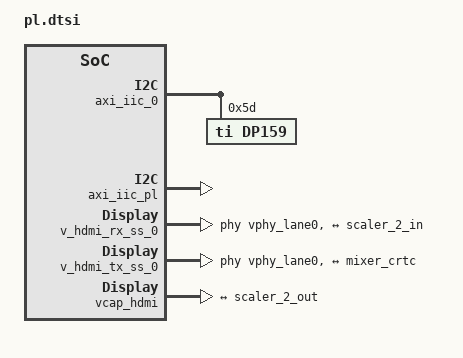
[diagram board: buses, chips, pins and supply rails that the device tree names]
/*
 * CAUTION: This file is automatically generated by Xilinx.
 * Version: XSCT 2018.3
 * Today is: Fri Feb  1 12:27:28 2019
 */


/ {
	amba_pl: amba_pl@0 {
		#address-cells = <2>;
		#size-cells = <2>;
		compatible = "simple-bus";
		ranges ;
		axi_iic_0: i2c@a000b000 {
			#address-cells = <1>;
			#size-cells = <0>;
			clock-names = "s_axi_aclk";
			clocks = <&misc_clk_0>;
			compatible = "xlnx,xps-iic-2.00.a";
			interrupt-names = "iic2intc_irpt";
			interrupt-parent = <&axi_intc_0>;
			interrupts = <4 2>;
			reg = <0x0 0xa000b000 0x0 0x1000>;
			
			dp159: hdmi-retimer@5d {
				status = "okay";
				compatible = "ti,dp159";
				reg = <0x5d>;
				#address-cells = <1>;
				#size-cells = <0>;
				#clock-cells = <0>;
			};
		};
		axi_iic_pl: i2c@a0003000 {
			#address-cells = <1>;
			#size-cells = <0>;
			clock-names = "s_axi_aclk";
			clocks = <&misc_clk_0>;
			compatible = "xlnx,xps-iic-2.00.a";
			interrupt-names = "iic2intc_irpt";
			interrupt-parent = <&axi_intc_0>;
			interrupts = <0 2>;
			reg = <0x0 0xa0003000 0x0 0x1000>;
		};
		axi_intc_0: interrupt-controller@a000a000 {
			#interrupt-cells = <2>;
			compatible = "xlnx,xps-intc-1.00.a";
			interrupt-controller ;
			interrupt-names = "irq";
			interrupt-parent = <&gic>;
			interrupts = <0 89 4>;
			reg = <0x0 0xa000a000 0x0 0x1000>;
			xlnx,kind-of-intr = <0x0>;
			xlnx,num-intr-inputs = <0x7>;
		};
		psu_ctrl_ipi: PERIPHERAL@ff380000 {
			/* This is a place holder node for a custom IP, user may need to update the entries */
			compatible = "xlnx,PERIPHERAL-1.0";
			reg = <0x0 0xff380000 0x0 0x80000>;
		};
		psu_message_buffers: PERIPHERAL@ff990000 {
			/* This is a place holder node for a custom IP, user may need to update the entries */
			compatible = "xlnx,PERIPHERAL-1.0";
			reg = <0x0 0xff990000 0x0 0x10000>;
		};
		v_frmbuf_wr_0: v_frmbuf_wr@b0000000 {
			/* This is a place holder node for a custom IP, user may need to update the entries */
			#dma-cells = <1>;
			compatible = "xlnx,axi-frmbuf-wr-v2";
			interrupt-names = "interrupt";
			interrupt-parent = <&axi_intc_0>;
			interrupts = <6 2>;
			reg = <0x0 0xb0000000 0x0 0x10000>;
			reset-gpios = <&gpio 80 1>;
			xlnx,dma-addr-width = <32>;
			xlnx,s-axi-ctrl-addr-width = <0x7>;
			xlnx,s-axi-ctrl-data-width = <0x20>;
			xlnx,vid-formats = "yuyv","uyvy","y8";
		};
		v_hdmi_rx_ss_0: v_hdmi_rx_ss@a0010000 {
			/* This is a place holder node for a custom IP, user may need to update the entries */
			compatible = "xlnx,v-hdmi-rx-ss-3.1";
			interrupt-names = "irq";
			interrupt-parent = <&axi_intc_0>;
			interrupts = <5 2>;
			reg = <0x0 0xa0010000 0x0 0x10000>;
			
			clocks = <&misc_clk_0>, <&misc_clk_1>;
			clock-names = "axi-lite", "video";
			
			phy-names = "hdmi-phy0", "hdmi-phy1", "hdmi-phy2";
			phys = <&vphy_lane0 0 1 1 0>, <&vphy_lane1 0 1 1 0>, <&vphy_lane2 0 1 1 0>;
			
			xlnx,input-pixels-per-clock = <0x2>;

			/*xlnx,add-mark-dbg = "false";
			xlnx,addr-width = <0xa>;
			xlnx,cd-invert = "false";

			xlnx,exdes-axilite-freq = <0x64>;
			xlnx,exdes-nidru = "true";
			xlnx,exdes-rx-pll-selection = <0x0>;
			xlnx,exdes-topology = <0x0>;
			xlnx,exdes-tx-pll-selection = <0x1>;
			xlnx,hdmi-fast-switch = "false";
			xlnx,hdmi-version = <0x3>;
			xlnx,hpd-invert = "false";
			xlnx,include-hdcp-1-4 = "false";
			xlnx,include-hdcp-2-2 = "false";
			xlnx,include-low-reso-vid = "false";
			xlnx,include-yuv420-sup = "true";

			xlnx,max-bits-per-component = <0x8>;
			xlnx,validation-enable = "false";
			xlnx,vid-interface = <0x0>;*/
						
			ports {
				#address-cells = <1>;
				#size-cells = <0>;

				port@0 {
					reg = <0>;

					xlnx,video-format = <2>;
					xlnx,video-width = <8>;

					hdmi_rxss_out: endpoint {
						remote-endpoint = <&scaler_2_in>;
					};
				};
			};
		};
		v_hdmi_tx_ss_0: v_hdmi_tx_ss@a0020000 {
			/* This is a place holder node for a custom IP, user may need to update the entries */
			compatible = "xlnx,v-hdmi-tx-ss-3.1";

			interrupt-names = "irq";
			interrupt-parent = <&axi_intc_0>;
			interrupts = <2 2>;

			reg = <0x0 0xa0020000 0x0 0x20000>;

			clocks = <&misc_clk_0>, <&misc_clk_1>, <&si570>, <&dp159>;
			clock-names = "axi-lite", "video", "txref-clk", "retimer-clk";

			phy-names = "hdmi-phy0", "hdmi-phy1", "hdmi-phy2";
			phys = <&vphy_lane0 0 1 1 1>, <&vphy_lane1 0 1 1 1>, <&vphy_lane2 0 1 1 1>;

			/*xlnx,add-mark-dbg = "false";
			xlnx,addr-width = <0xa>;
			xlnx,exdes-axilite-freq = <0x64>;
			xlnx,exdes-nidru = "false";
			xlnx,exdes-rx-pll-selection = <0x0>;
			xlnx,exdes-topology = <0x1>;
			xlnx,exdes-tx-pll-selection = <0x6>;
			xlnx,hdmi-fast-switch = "false";
			xlnx,hdmi-version = <0x3>;
			xlnx,hpd-invert = "false";
			xlnx,hysteresis-level = <0xc>;
			xlnx,include-hdcp-1-4 = "false";
			xlnx,include-hdcp-2-2 = "false";
			xlnx,include-low-reso-vid = "false";
			xlnx,include-yuv420-sup = "true";

			xlnx,validation-enable = "false";
			xlnx,vid-interface = <0x0>;
			xlnx,video-mask-enable = <0x1>;*/

			xlnx,output-fmt = "rgb";
			xlnx,input-pixels-per-clock = <0x2>;
			xlnx,max-bits-per-component = <0x8>;
			
			ports {
				#address-cells = <1>;
				#size-cells = <0>;
				encoder_hdmi_port: port@0 {
					reg = <0>;
					hdmi_encoder: endpoint {
						remote-endpoint = <&mixer_crtc>;
					};
				};
			};
		};
		v_mix_0: v_mix@b0010000 {
			/* This is a place holder node for a custom IP, user may need to update the entries */
			compatible = "xlnx,v-mix-3.0", "xlnx,mixer-3.0";
			interrupt-names = "interrupt";
			interrupt-parent = <&axi_intc_0>;
			interrupts = <1 2>;
			reg = <0x0 0xb0010000 0x0 0x10000>;
			xlnx,s-axi-ctrl-addr-width = <0xc>;
			xlnx,s-axi-ctrl-data-width = <0x20>;
			reset-gpios = <&gpio 79 1>;
			clocks = <&si570>;
			xlnx,connector-type = "HDMIA";
			xlnx,dma-addr-width=<32>;

			xlnx,bpc = <8>;
			xlnx,ppc = <2>;
			xlnx,num-layers = <5>;

			crtc_mixer_port: port@0 {
					reg = <0>;
					mixer_crtc: endpoint {
					remote-endpoint = <&hdmi_encoder>;
				};
			};

			mixer_master_layer: layer_0 {
				xlnx,layer-id = <0>;
				xlnx,layer-max-width = <3840>;
				xlnx,layer-max-height = <2160>;
				xlnx,vformat = "BG24";
			};
			mixer_overlay_1: layer_1 {
				xlnx,layer-id = <1>;
				xlnx,vformat = "YUYV";
				xlnx,layer-alpha;
				xlnx,layer-max-width = <3840>;
			};
			mixer_overlay_2: layer_2 {
				xlnx,layer-id = <2>;
				xlnx,vformat = "YUYV";
				xlnx,layer-alpha;
				xlnx,layer-max-width = <3840>;
			};
			mixer_overlay_3: layer_3 {
				xlnx,layer-id = <3>;
				xlnx,vformat = "UYVY";
				xlnx,layer-alpha;
				xlnx,layer-max-width = <3840>;
			};
			mixer_overlay_4: layer_4 {
				xlnx,layer-id = <4>;
				xlnx,vformat = "AR24";
				xlnx,layer-alpha;
				xlnx,layer-max-width = <3840>;
				xlnx,layer-primary;
			};
			xv_mix_logo: logo {
				xlnx,layer-id = <5>;
				xlnx,logo-height = <64>;
				xlnx,logo-width = <64>;
			};
		};
		v_proc_ss_scaler: v_proc_ss@b0040000 {
			/* This is a place holder node for a custom IP, user may need to update the entries */
			//compatible = "xlnx,v-proc-ss-2.0";
			compatible = "xlnx,v-vpss-scaler";
			reg = <0x0 0xb0040000 0x0 0x40000>;
			
			/*xlnx,aximm-addr-width = <0x20>;
			xlnx,aximm-burst-length = <0x10>;
			xlnx,aximm-num-outstanding = <0x10>;
			xlnx,chroma-algorithm = <0x2>;
			xlnx,colorspace-support = <0x0>;
			xlnx,csc-enable-422 = "true";
			xlnx,csc-enable-window = "true";
			xlnx,deint-motion-adaptive = "true";
			xlnx,enable-csc = "true";
			xlnx,enable-dma = "true";
			xlnx,enable-interlaced = "true";
			xlnx,h-chroma-algorithm = <0x2>;
			xlnx,h-chroma-taps = <0x4>;
			xlnx,h-scaler-phases = <0x40>;
			xlnx,h-scaler-taps = <0x8>;
			xlnx,max-cols = <0xf00>;
			xlnx,max-data-width = <0x8>;
			xlnx,max-rows = <0x870>;
			xlnx,num-video-components = <0x3>;
			xlnx,samples-per-clk = <0x2>;
			xlnx,scaler-algorithm = <0x2>;
			xlnx,scaler-enable-422 = "true";
			xlnx,topology = <0x0>;
			xlnx,use-uram = <0x0>;
			xlnx,v-chroma-algorithm = <0x2>;
			xlnx,v-chroma-taps = <0x4>;
			xlnx,v-scaler-phases = <0x40>;
			xlnx,v-scaler-taps = <0x8>;*/

			clocks = <&misc_clk_1>;
			xlnx,num-hori-taps = <8>;
			xlnx,num-vert-taps = <8>;
			xlnx,pix-per-clk = <2>;
			reset-gpios = <&gpio 78 1>;
			
			ports {
				#address-cells = <1>;
				#size-cells = <0>;

				port@0 {
					reg = <0>;

					xlnx,video-format = <2>;
					xlnx,video-width = <8>;

					scaler_2_in: endpoint {
						remote-endpoint = <&hdmi_rxss_out>;
					};
				};
				port@1 {
					reg = <1>;

					xlnx,video-format = <0>;
					xlnx,video-width = <8>;

					scaler_2_out: endpoint {
						remote-endpoint = <&vcap_hdmi_in>;
					};
				};
			};
		};
		vcap_hdmi {
			compatible = "xlnx,video";
			dmas = <&v_frmbuf_wr_0 0>;
			dma-names = "port0";

			ports {
				#address-cells = <1>;
				#size-cells = <0>;

				port@0 {
					reg = <0>;
					direction = "input";
					vcap_hdmi_in: endpoint {
						remote-endpoint = <&scaler_2_out>;
					};
				};
			};
		};
		vid_phy_controller_0: vid_phy_controller@a0060000 {
			/* This is a place holder node for a custom IP, user may need to update the entries */
			compatible = "xlnx,vid-phy-controller-2.2";
			interrupt-names = "irq";
			interrupt-parent = <&axi_intc_0>;
			interrupts = <3 2>;
			reg = <0x0 0xa0060000 0x0 0x10000>;
			
			clocks = <&misc_clk_0>, <&nidru>;
			clock-names = "axi-lite", "dru-clk";

			xlnx,axi4lite-enable = "true";
			xlnx,component-name = "TySOM_3_ZU7_vid_phy_controller_0_0";
			xlnx,device = "xczu7ev";
			xlnx,dru-gain-g1 = <0x9>;
			xlnx,dru-gain-g1-p = <0x10>;
			xlnx,dru-gain-g2 = <0x4>;
			xlnx,dru-refclk-fabric-buffer = "none";
			xlnx,err-irq-en = <0x0>;
			xlnx,for-upgrade-architecture = "placeholder";
			xlnx,for-upgrade-device = "placeholder";
			xlnx,for-upgrade-maxoptvol = "0.00";
			xlnx,for-upgrade-package = "placeholder";
			xlnx,for-upgrade-part = "placeholder";
			xlnx,for-upgrade-refvol = "0.00";
			xlnx,for-upgrade-speedgrade = <0x0>;
			xlnx,hdmi-fast-switch = <0x1>;
			xlnx,input-pixels-per-clock = <0x2>;
			xlnx,int-hdmi-ver-cmptble = <0x3>;

			xlnx,nidru = <0x1>;
			xlnx,nidru-refclk-sel = <0x3>;
			xlnx,rx-gt-debug-ports = "false";
			xlnx,rx-no-of-channels = <0x3>;
			xlnx,rx-outclk-buffer = "none";
			xlnx,rx-pll-selection = <0x0>;
			xlnx,rx-protocol = <0x1>;
			xlnx,rx-raw-mode-en = "false";
			xlnx,rx-refclk-sel = <0x1>;
			xlnx,rx-sb-ports = "true";
			xlnx,rx-tmds-clk-buffer = "bufg";
			xlnx,rx-video-clk-buffer = "bufg";
			xlnx,silicon-revision = <0x0>;
			xlnx,speedgrade = "-2";
			xlnx,supportlevel = <0x1>;

			xlnx,transceivercontrol = "false";
			xlnx,tx-gt-debug-ports = "false";
			xlnx,tx-no-of-channels = <0x3>;
			xlnx,tx-outclk-buffer = "none";
			xlnx,tx-pll-selection = <0x6>;
			xlnx,tx-protocol = <0x1>;
			xlnx,tx-raw-mode-en = "false";
			xlnx,tx-refclk-fabric-buffer = "none";
			xlnx,tx-refclk-sel = <0x0>;
			xlnx,tx-sb-ports = "true";
			xlnx,tx-tmds-clk-buffer = "bufg";
			xlnx,tx-video-clk-buffer = "bufg";
			xlnx,txpi-port-en = "false";
			xlnx,txrefclk-rdy-invert = <0x1>;
			xlnx,use-gt-ch4-hdmi = <0x0>;
			xlnx,use-oddr-for-tmds-clkout = "true";

			xlnx,vid-phy-axi4lite-addr-width = <0xa>;
			xlnx,vid-phy-axi4lite-data-width = <0x20>;
			xlnx,vid-phy-control-sb-rx-tdata-width = <0x1>;
			xlnx,vid-phy-control-sb-tx-tdata-width = <0x1>;
			xlnx,vid-phy-rx-axi4s-ch-int-tdata-width = <0x14>;
			xlnx,vid-phy-rx-axi4s-ch-tdata-width = <0x14>;
			xlnx,vid-phy-rx-axi4s-ch-tuser-width = <0x1>;
			xlnx,vid-phy-status-sb-rx-tdata-width = <0x2>;
			xlnx,vid-phy-status-sb-tx-tdata-width = <0x2>;
			xlnx,vid-phy-tx-axi4s-ch-int-tdata-width = <0x14>;
			xlnx,vid-phy-tx-axi4s-ch-tdata-width = <0x14>;
			xlnx,vid-phy-tx-axi4s-ch-tuser-width = <0x1>;
			xlnx,viper-reg = "false";
			
			xlnx,transceiver-type = <0x5>;
			xlnx,tx-buffer-bypass = <0x1>;
			xlnx,transceiver-width = <0x2>;

			vphy_lane0: vphy_lane@0 {
				#phy-cells = <4>;
			};
			vphy_lane1: vphy_lane@1 {
				#phy-cells = <4>;
			};
			vphy_lane2: vphy_lane@2 {
				#phy-cells = <4>;
			};
			vphy_lane3: vphy_lane@3 {
				#phy-cells = <4>;
			};
		};
		wl18xx_ctrl: gpio@a0002000 {
			#gpio-cells = <3>;
			clock-names = "s_axi_aclk";
			clocks = <&misc_clk_0>;
			compatible = "xlnx,xps-gpio-1.00.a";
			gpio-controller ;
			reg = <0x0 0xa0002000 0x0 0x1000>;
			xlnx,all-inputs = <0x0>;
			xlnx,all-inputs-2 = <0x0>;
			xlnx,all-outputs = <0x1>;
			xlnx,all-outputs-2 = <0x0>;
			xlnx,dout-default = <0x00000000>;
			xlnx,dout-default-2 = <0x00000000>;
			xlnx,gpio-width = <0x2>;
			xlnx,gpio2-width = <0x20>;
			xlnx,interrupt-present = <0x0>;
			xlnx,is-dual = <0x0>;
			xlnx,tri-default = <0xFFFFFFFF>;
			xlnx,tri-default-2 = <0xFFFFFFFF>;
		};
		misc_clk_0: misc_clk_0 {
			#clock-cells = <0>;
			clock-frequency = <50000000>;
			compatible = "fixed-clock";
		};
		misc_clk_1: misc_clk_1 {
			#clock-cells = <0>;
			clock-frequency = <300000000>;
			compatible = "fixed-clock";
		};
		nidru: nidru {
			#clock-cells = <0>;
			clock-frequency = <156250000>;
			compatible = "fixed-clock";
		};
	};
};
&sata {
	ceva,p0-burst-params = /bits/ 8 <0x13 0x08 0x4A 0x06>;
	ceva,p0-cominit-params = /bits/ 8 <0x18 0x40 0x18 0x28>;
	ceva,p0-comwake-params = /bits/ 8 <0x06 0x14 0x08 0x0E>;
	ceva,p0-retry-params = /bits/ 16 <0x96A4 0x3FFC>;
	ceva,p1-burst-params = /bits/ 8 <0x13 0x08 0x4A 0x06>;
	ceva,p1-cominit-params = /bits/ 8 <0x18 0x40 0x18 0x28>;
	ceva,p1-comwake-params = /bits/ 8 <0x06 0x14 0x08 0x0E>;
	ceva,p1-retry-params = /bits/ 16 <0x96A4 0x3FFC>;
};
